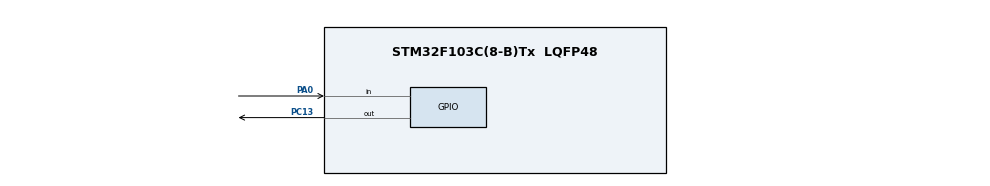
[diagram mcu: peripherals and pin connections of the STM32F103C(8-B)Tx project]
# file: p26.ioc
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Mcu.Family=STM32F1
Mcu.Name=STM32F103C(8-B)Tx
Mcu.Package=LQFP48
NVIC.PriorityGroup=NVIC_PRIORITYGROUP_4
PA0-WKUP.GPIO_PuPd=GPIO_PULLUP
PA0-WKUP.Signal=GPIO_Input
PA13.Mode=Serial_Wire
PA13.Signal=SYS_JTMS-SWDIO
PA14.Mode=Serial_Wire
PA14.Signal=SYS_JTCK-SWCLK
PC13-TAMPER-RTC.PinState=GPIO_PIN_SET
PC13-TAMPER-RTC.Signal=GPIO_Output
PD0-OSC_IN.Mode=HSE-External-Oscillator
PD0-OSC_IN.Signal=RCC_OSC_IN
PD1-OSC_OUT.Mode=HSE-External-Oscillator
PD1-OSC_OUT.Signal=RCC_OSC_OUT
ProjectManager.HeapSize=0x200
ProjectManager.StackSize=0x400
ProjectManager.TargetToolchain=STM32CubeIDE
RCC.APB1Freq_Value=8000000
RCC.APB2Freq_Value=8000000
RCC.SYSCLKSource=RCC_SYSCLKSOURCE_HSE
TIM2.Period=65536 - 1
TIM2.Prescaler=8000 - 1
TIM3.AutoReloadPreload=TIM_AUTORELOAD_PRELOAD_ENABLE
TIM3.Period=65536 - 1
TIM3.Prescaler=8000 - 1
VP_TIM2_VS_ClockSourceINT.Mode=Internal
VP_TIM3_VS_ClockSourceINT.Mode=Internal
board=custom

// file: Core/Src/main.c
/* USER CODE BEGIN Header */
/**
 ******************************************************************************
 * @file           : main.c
 * @brief          : Main program body
 ******************************************************************************
 * @attention
 *
 * Copyright (c) 2025 STMicroelectronics.
 * All rights reserved.
 *
 * This software is licensed under terms that can be found in the LICENSE file
 * in the root directory of this software component.
 * If no LICENSE file comes with this software, it is provided AS-IS.
 *
 ******************************************************************************
 */
/* USER CODE END Header */
#include "main.h"

TIM_HandleTypeDef htim2;
TIM_HandleTypeDef htim3;

void SystemClock_Config(void);
static void MX_GPIO_Init(void);
static void MX_TIM2_Init(void);
static void MX_TIM3_Init(void);
/* USER CODE BEGIN PFP */
uint8_t debounce_timer(GPIO_TypeDef *GPIOx, uint16_t GPIO_Pin);
/* USER CODE END PFP */

int main(void)
{

  /* MCU Configuration--------------------------------------------------------*/

  /* Reset of all peripherals, Initializes the Flash interface and the Systick. */
  HAL_Init();

  /* Configure the system clock */
  SystemClock_Config();

  /* Initialize all configured peripherals */
  MX_GPIO_Init();
  MX_TIM2_Init();
  MX_TIM3_Init();
  /* USER CODE BEGIN 2 */
  HAL_TIM_Base_Start(&htim2);  //Inicializa o timer 2
  HAL_TIM_Base_Start(&htim3);  //Inicializa o timer 3
  uint8_t pressed = 0;
  uint8_t triggered = 0;
  /* USER CODE END 2 */

  /* Infinite loop */
  /* USER CODE BEGIN WHILE */
  while(1)
  {
    /*Aqui no loop, usei a função debouce_timer para verificar o acionamento do botão. A cada vez que é pressionado,
     * é incrementado a variável pressed, que começa com 0. O valor resultante é dividido por 4, e o resto é
     * atribuido à própria variável, sendo sendo de 0 a 3. Caso o botão seja pressionado, a variável trigged recebe
     * 1, e a partir de então, é executado o código.*/
    if(debounce_timer(GPIOA, GPIO_PIN_0) == GPIO_PIN_RESET)
    {
      pressed = (pressed + 1) % 4;
      triggered = 1;
      while(HAL_GPIO_ReadPin(GPIOA, GPIO_PIN_0) == GPIO_PIN_RESET); //Aguarda o botão ser liberado
    }
    if(triggered)
    {
      if(pressed == 1)
      {
	/* Pisca 3 vezes com HAL. O valor 6, indica que serão 3 vezes para ligar e 3 para desligar, com um
	 * delay de 500 ms a cada execução alternada.*/
	for(uint8_t i = 0; i < 6; i++)
	{
	  HAL_GPIO_TogglePin(GPIOC, GPIO_PIN_13);
	  HAL_Delay(500);
	}
      }
      else if(pressed == 2)
      {
	/* Pisca 3 vezes com CMSIS. Usa o registrador GPIOC->ODR e uma máscara (1 << 13) em uma operação
	 * XOR.*/
	for(uint8_t i = 0; i < 6; i++)
	{
	  GPIOC->ODR ^= (1 << 13);
	  uint32_t now = HAL_GetTick();
	  while((HAL_GetTick() - now) <= 1000);
	}
      }
      else if(pressed == 3)
      {
	/* Pisca 3 vezes usando bare metal. Escrever no endereço 0x4001100C manipula a saída da porta c, sendo
	 *  usado neste caso somente o bit 13 com uma operação XOR com o valor do registrador.*/
	volatile uint32_t *GPIOC_ODR = (volatile uint32_t*)0x4001100C;
	for(uint8_t i = 0; i < 6; i++)
	{
	  *GPIOC_ODR ^= (1 << 13);
	  uint16_t now = TIM3->CNT;
	  while(TIM3->CNT - now <= 2000);
	}
      }
      triggered = 0; //Após a execução de um dos meios, triggered recebe 0 e só muda em um novo acionamento do botão
    }
    /* USER CODE END WHILE */

  }
}

void SystemClock_Config(void)
{
  RCC_OscInitTypeDef RCC_OscInitStruct = {0};
  RCC_ClkInitTypeDef RCC_ClkInitStruct = {0};

  /** Initializes the RCC Oscillators according to the specified parameters
   * in the RCC_OscInitTypeDef structure.
   */
  RCC_OscInitStruct.OscillatorType = RCC_OSCILLATORTYPE_HSE;
  RCC_OscInitStruct.HSEState = RCC_HSE_ON;
  RCC_OscInitStruct.PLL.PLLState = RCC_PLL_NONE;
  if (HAL_RCC_OscConfig(&RCC_OscInitStruct) != HAL_OK)
    {
      Error_Handler();
    }

  /** Initializes the CPU, AHB and APB buses clocks
   */
  RCC_ClkInitStruct.ClockType = RCC_CLOCKTYPE_HCLK|RCC_CLOCKTYPE_SYSCLK
      |RCC_CLOCKTYPE_PCLK1|RCC_CLOCKTYPE_PCLK2;
  RCC_ClkInitStruct.SYSCLKSource = RCC_SYSCLKSOURCE_HSE;
  RCC_ClkInitStruct.AHBCLKDivider = RCC_SYSCLK_DIV1;
  RCC_ClkInitStruct.APB1CLKDivider = RCC_HCLK_DIV1;
  RCC_ClkInitStruct.APB2CLKDivider = RCC_HCLK_DIV1;

  if (HAL_RCC_ClockConfig(&RCC_ClkInitStruct, FLASH_LATENCY_0) != HAL_OK)
    {
      Error_Handler();
    }
}

static void MX_TIM2_Init(void)
{

  TIM_ClockConfigTypeDef sClockSourceConfig = {0};
  TIM_MasterConfigTypeDef sMasterConfig = {0};

  htim2.Instance = TIM2;
  htim2.Init.Prescaler = 8000 - 1;
  htim2.Init.CounterMode = TIM_COUNTERMODE_UP;
  htim2.Init.Period = 65536 - 1;
  htim2.Init.ClockDivision = TIM_CLOCKDIVISION_DIV1;
  htim2.Init.AutoReloadPreload = TIM_AUTORELOAD_PRELOAD_DISABLE;
  if (HAL_TIM_Base_Init(&htim2) != HAL_OK)
    {
      Error_Handler();
    }
  sClockSourceConfig.ClockSource = TIM_CLOCKSOURCE_INTERNAL;
  if (HAL_TIM_ConfigClockSource(&htim2, &sClockSourceConfig) != HAL_OK)
    {
      Error_Handler();
    }
  sMasterConfig.MasterOutputTrigger = TIM_TRGO_RESET;
  sMasterConfig.MasterSlaveMode = TIM_MASTERSLAVEMODE_DISABLE;
  if (HAL_TIMEx_MasterConfigSynchronization(&htim2, &sMasterConfig) != HAL_OK)
    {
      Error_Handler();
    }

}

static void MX_TIM3_Init(void)
{

  TIM_ClockConfigTypeDef sClockSourceConfig = {0};
  TIM_MasterConfigTypeDef sMasterConfig = {0};

  htim3.Instance = TIM3;
  htim3.Init.Prescaler = 8000 - 1;
  htim3.Init.CounterMode = TIM_COUNTERMODE_UP;
  htim3.Init.Period = 65536 - 1;
  htim3.Init.ClockDivision = TIM_CLOCKDIVISION_DIV1;
  htim3.Init.AutoReloadPreload = TIM_AUTORELOAD_PRELOAD_ENABLE;
  if (HAL_TIM_Base_Init(&htim3) != HAL_OK)
    {
      Error_Handler();
    }
  sClockSourceConfig.ClockSource = TIM_CLOCKSOURCE_INTERNAL;
  if (HAL_TIM_ConfigClockSource(&htim3, &sClockSourceConfig) != HAL_OK)
    {
      Error_Handler();
    }
  sMasterConfig.MasterOutputTrigger = TIM_TRGO_RESET;
  sMasterConfig.MasterSlaveMode = TIM_MASTERSLAVEMODE_DISABLE;
  if (HAL_TIMEx_MasterConfigSynchronization(&htim3, &sMasterConfig) != HAL_OK)
    {
      Error_Handler();
    }

}

static void MX_GPIO_Init(void)
{
  GPIO_InitTypeDef GPIO_InitStruct = {0};

  /* GPIO Ports Clock Enable */
  __HAL_RCC_GPIOC_CLK_ENABLE();
  __HAL_RCC_GPIOD_CLK_ENABLE();
  __HAL_RCC_GPIOA_CLK_ENABLE();

  /*Configure GPIO pin Output Level */
  HAL_GPIO_WritePin(GPIOC, GPIO_PIN_13, GPIO_PIN_SET);

  /*Configure GPIO pin : PC13 */
  GPIO_InitStruct.Pin = GPIO_PIN_13;
  GPIO_InitStruct.Mode = GPIO_MODE_OUTPUT_PP;
  GPIO_InitStruct.Pull = GPIO_NOPULL;
  GPIO_InitStruct.Speed = GPIO_SPEED_FREQ_LOW;
  HAL_GPIO_Init(GPIOC, &GPIO_InitStruct);

  /*Configure GPIO pin : PA0 */
  GPIO_InitStruct.Pin = GPIO_PIN_0;
  GPIO_InitStruct.Mode = GPIO_MODE_INPUT;
  GPIO_InitStruct.Pull = GPIO_PULLUP;
  HAL_GPIO_Init(GPIOA, &GPIO_InitStruct);

}

/* USER CODE BEGIN 4 */
/*Função que implementa o debounce para verificar estado do pino PA0, onde está o botão.
 * É utilizado o timer2 como base de tempo para evitar multiplas leituras, sendo necessário pelo
 * menos 100 ms entre as leituras, conforme o código.
 * A varivável "now" recebe o valor atual do contador do timer 2. No segundo if, ao testar se a diferença
 * entre o valor atual do contador e o valor de "now" for maior ou igual a 100, a função retorna 0. Caso contrário,
 * retorna 1.*/
uint8_t debounce_timer(GPIO_TypeDef *GPIOx, uint16_t GPIO_Pin)
{
  static uint32_t now = 0;
  if(HAL_GPIO_ReadPin(GPIOx, GPIO_Pin) == 0)
  {
    if(TIM2->CNT - now >= 100)
    {
      now = TIM2->CNT;
      return 0;
    }
  }
  return 1;
}
/* USER CODE END 4 */

void Error_Handler(void)
{
  __disable_irq();
  while (1)
    {
    }
}
